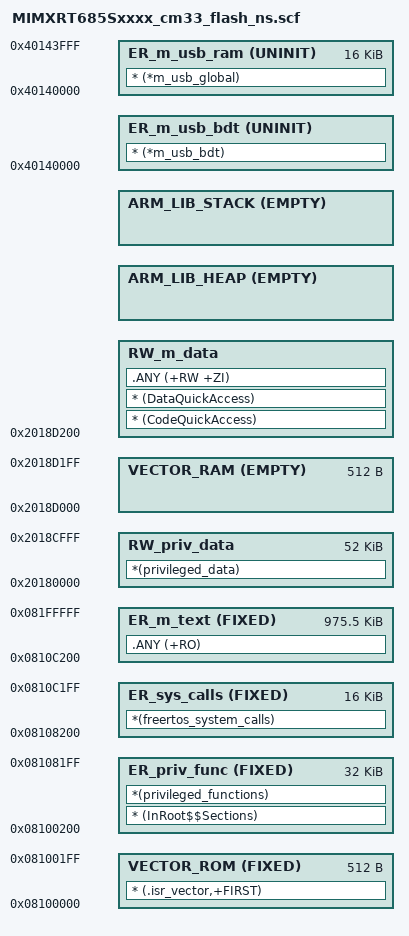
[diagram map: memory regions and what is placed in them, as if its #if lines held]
#!armclang --target=arm-arm-none-eabi -march=armv8-m.main -E -x c
/*
** ###################################################################
**     Processors:          MIMXRT685SFAWBR_cm33
**                          MIMXRT685SFFOB_cm33
**                          MIMXRT685SFVKB_cm33
**
**     Compiler:            Keil ARM C/C++ Compiler
**     Reference manual:    MIMXRT685 User manual Rev. 0.95 11 November 2019
**     Version:             rev. 1.0, 2018-06-19
**     Build:               b201029
**
**     Abstract:
**         Linker file for the Keil ARM C/C++ Compiler
**
**     Copyright 2016 Freescale Semiconductor, Inc.
**     Copyright 2016-2020 NXP
**     All rights reserved.
**
**     SPDX-License-Identifier: BSD-3-Clause
**
**     http:                 www.nxp.com
**     mail:                 support@nxp.com
**
** ###################################################################
*/


/* USB BDT size */
#define usb_bdt_size                   0x0
/* Sizes */
#if (defined(__stack_size__))
  #define Stack_Size                   __stack_size__
#else
  #define Stack_Size                   0x0400
#endif

#if (defined(__heap_size__))
  #define Heap_Size                    __heap_size__
#else
  #define Heap_Size                    0x0400
#endif

/* The SRAM region [0x10000-0x1BFFF] is reserved for ROM code. */
/* The SRAM region [0x0-0xFFFF], [0x1C000-0x1FFFF] is reserved for app-specific use cases. */
/* The SRAM region [0x20000-0x7FFFF] is reserved for Non-cached shared memory between M33 and DSP. */

#if (defined(__ram_vector_table__))
  #define __ram_vector_table_size__    0x00000200
#else
  #define __ram_vector_table_size__    0x00000000
#endif

#define  m_interrupts_start            0x08100000
#define  m_interrupts_size             0x00000200

#define  priv_func_start               0x08100200
#define  priv_func_size                0x00008000

#define  sys_calls_start               0x08108200
#define  sys_calls_size                0x00004000

#define  m_text_start                  0x0810C200
#define  m_text_size                   0x000F3E00

#define  priv_data_start               0x20180000
#define  priv_data_size                0x0000D000

#define m_interrupts_ram_start         0x2018D000
#define m_interrupts_ram_size          __ram_vector_table_size__

#define  m_data_start                  (m_interrupts_ram_start + m_interrupts_ram_size)
#define  m_data_size                   (0x00080000 - m_interrupts_ram_size - priv_data_size)

#define  m_usb_sram_start              0x40140000
#define  m_usb_sram_size               0x00004000


LR_m_interrupts m_interrupts_start m_interrupts_size+m_text_size {
  VECTOR_ROM m_interrupts_start FIXED m_interrupts_size { ; load address = execution address
    * (.isr_vector,+FIRST)
  }

  ER_priv_func priv_func_start FIXED priv_func_size { ; load address = execution address
    * (InRoot$$Sections)
    *(privileged_functions)
  }

  ER_sys_calls sys_calls_start FIXED sys_calls_size { ; load address = execution address
    *(freertos_system_calls)
  }

  ER_m_text m_text_start FIXED m_text_size { ; load address = execution address
    .ANY (+RO)
  }

  RW_priv_data priv_data_start priv_data_size { ; privileged data
    *(privileged_data)
  }

#if (defined(__ram_vector_table__))
  VECTOR_RAM m_interrupts_ram_start EMPTY m_interrupts_ram_size {
  }
#else
  VECTOR_RAM m_interrupts_start EMPTY 0 {
  }
#endif
  RW_m_data m_data_start ALIGN 4 m_data_size-Stack_Size-Heap_Size { ; RW data
    * (CodeQuickAccess)
    * (DataQuickAccess)
    .ANY (+RW +ZI)
  }

  ARM_LIB_HEAP +0 EMPTY Heap_Size {    ; Heap region growing up
  }
  ARM_LIB_STACK m_data_start+m_data_size EMPTY -Stack_Size { ; Stack region growing down
  }

  ER_m_usb_bdt m_usb_sram_start UNINIT usb_bdt_size {
    * (*m_usb_bdt)
  }

  ER_m_usb_ram (m_usb_sram_start + usb_bdt_size) UNINIT (m_usb_sram_size - usb_bdt_size) {
    * (*m_usb_global)
  }
}
